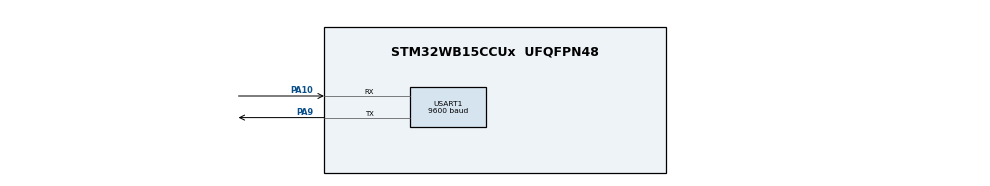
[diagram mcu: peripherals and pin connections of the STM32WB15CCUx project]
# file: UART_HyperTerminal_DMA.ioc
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Dma.Request0=USART1_RX
Dma.Request1=USART1_TX
Dma.USART1_RX.0.Direction=DMA_PERIPH_TO_MEMORY
Dma.USART1_RX.0.EventEnable=DISABLE
Dma.USART1_RX.0.Instance=DMA1_Channel2
Dma.USART1_RX.0.MemDataAlignment=DMA_MDATAALIGN_BYTE
Dma.USART1_RX.0.MemInc=DMA_MINC_ENABLE
Dma.USART1_RX.0.Mode=DMA_NORMAL
Dma.USART1_RX.0.PeriphDataAlignment=DMA_PDATAALIGN_BYTE
Dma.USART1_RX.0.PeriphInc=DMA_PINC_DISABLE
Dma.USART1_RX.0.Polarity=HAL_DMAMUX_REQ_GEN_RISING
Dma.USART1_RX.0.Priority=DMA_PRIORITY_HIGH
Dma.USART1_RX.0.RequestNumber=1
Dma.USART1_RX.0.SignalID=NONE
Dma.USART1_RX.0.SyncEnable=DISABLE
Dma.USART1_RX.0.SyncPolarity=HAL_DMAMUX_SYNC_NO_EVENT
Dma.USART1_RX.0.SyncRequestNumber=1
Dma.USART1_RX.0.SyncSignalID=NONE
Dma.USART1_TX.1.Direction=DMA_MEMORY_TO_PERIPH
Dma.USART1_TX.1.EventEnable=DISABLE
Dma.USART1_TX.1.Instance=DMA1_Channel1
Dma.USART1_TX.1.MemDataAlignment=DMA_MDATAALIGN_BYTE
Dma.USART1_TX.1.MemInc=DMA_MINC_ENABLE
Dma.USART1_TX.1.Mode=DMA_NORMAL
Dma.USART1_TX.1.PeriphDataAlignment=DMA_PDATAALIGN_BYTE
Dma.USART1_TX.1.PeriphInc=DMA_PINC_DISABLE
Dma.USART1_TX.1.Polarity=HAL_DMAMUX_REQ_GEN_RISING
Dma.USART1_TX.1.Priority=DMA_PRIORITY_LOW
Dma.USART1_TX.1.RequestNumber=1
Dma.USART1_TX.1.SignalID=NONE
Dma.USART1_TX.1.SyncEnable=DISABLE
Dma.USART1_TX.1.SyncPolarity=HAL_DMAMUX_SYNC_NO_EVENT
Dma.USART1_TX.1.SyncRequestNumber=1
Dma.USART1_TX.1.SyncSignalID=NONE
Mcu.Family=STM32WB
Mcu.Name=STM32WB15CCUx
Mcu.Package=UFQFPN48
NVIC.DMA1_Channel1_IRQn=true\:0\:0\:false\:false\:true\:true\:true
NVIC.DMA1_Channel2_IRQn=true\:0\:0\:false\:false\:true\:true\:true
NVIC.PriorityGroup=NVIC_PRIORITYGROUP_4
NVIC.USART1_IRQn=true\:0\:0\:false\:false\:true\:true\:true
PA10.GPIO_PuPd=GPIO_PULLUP
PA10.Mode=Asynchronous
PA10.Signal=USART1_RX
PA9.GPIO_PuPd=GPIO_PULLUP
PA9.Mode=Asynchronous
PA9.Signal=USART1_TX
ProjectManager.HeapSize=0x200
ProjectManager.StackSize=0x400
ProjectManager.TargetToolchain=EWARM V8
RCC.AHB2CLKDivider=RCC_SYSCLK_DIV2
RCC.AHBFreq_Value=64000000
RCC.APB1Freq_Value=64000000
RCC.APB1TimFreq_Value=64000000
RCC.APB2Freq_Value=64000000
RCC.APB2TimFreq_Value=64000000
RCC.APB3Freq_Value=16000000
RCC.CortexFreq_Value=64000000
RCC.HCLKFreq_Value=64000000
RCC.HSE_VALUE=8000000
RCC.HSI_VALUE=16000000
RCC.LSE_VALUE=32768
RCC.PLLN=32
RCC.SYSCLKFreq_VALUE=64000000
RCC.SYSCLKSource=RCC_SYSCLKSOURCE_PLLCLK
RCC.VCOOutputFreq_Value=128000000
USART1.AutoBaudRateEnableParam=UART_ADVFEATURE_AUTOBAUDRATE_DISABLE
USART1.BaudRate=9600
USART1.DMADisableonRxErrorParam=ADVFEATURE_DMA_ENABLEONRXERROR
USART1.DataInvertParam=ADVFEATURE_DATAINV_DISABLE
USART1.MSBFirstParam=ADVFEATURE_MSBFIRST_DISABLE
USART1.Mode=MODE_TX_RX
USART1.OneBitSampling=UART_ONE_BIT_SAMPLE_DISABLE
USART1.OverSampling=UART_OVERSAMPLING_16
USART1.OverrunDisableParam=ADVFEATURE_OVERRUN_ENABLE
USART1.Parity=PARITY_ODD
USART1.RxPinLevelInvertParam=ADVFEATURE_RXINV_DISABLE
USART1.StopBits=STOPBITS_1
USART1.SwapParam=ADVFEATURE_SWAP_DISABLE
USART1.TxPinLevelInvertParam=ADVFEATURE_TXINV_DISABLE
USART1.VirtualMode-Asynchronous=VM_ASYNC
USART1.WordLength=WORDLENGTH_8B
board=custom

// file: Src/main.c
/* USER CODE BEGIN Header */
/**
  ******************************************************************************
  * @file    UART/UART_HyperTerminal_DMA/Src/main.c
  * @author  MCD Application Team
  * @brief   This sample code shows how to use UART HAL API to transmit
  *          and receive a data buffer with a communication process based on
  *          DMA transfer.
  *          The communication is done with the Hyperterminal PC application.
  ******************************************************************************
  * @attention
  *
  * <h2><center>&copy; Copyright (c) 2019 STMicroelectronics.
  * All rights reserved.</center></h2>
  *
  * This software component is licensed by ST under BSD 3-Clause license,
  * the "License"; You may not use this file except in compliance with the
  * License. You may obtain a copy of the License at:
  *                        opensource.org/licenses/BSD-3-Clause
  *
  ******************************************************************************
  */
/* USER CODE END Header */
#include "main.h"

UART_HandleTypeDef huart1;
DMA_HandleTypeDef hdma_usart1_rx;
DMA_HandleTypeDef hdma_usart1_tx;

/* USER CODE BEGIN PV */
/* Buffer used for transmission */
uint8_t aTxStartMessage[] = "\n\r ****UART-Hyperterminal communication based on DMA****\n\r Enter 10 characters using keyboard :\n\r";
uint8_t aTxEndMessage[] = "\n\r Example Finished\n\r";

/* Buffer used for reception */
uint8_t aRxBuffer[RXBUFFERSIZE];
/* USER CODE END PV */

void SystemClock_Config(void);
static void MX_GPIO_Init(void);
static void MX_DMA_Init(void);
static void MX_USART1_UART_Init(void);

int main(void)
{
  /* USER CODE BEGIN 1 */

  /* STM32WBxx HAL library initialization:
       - Configure the Flash prefetch
       - Systick timer is configured by default as source of time base, but user
         can eventually implement his proper time base source (a general purpose
         timer for example or other time source), keeping in mind that Time base
         duration should be kept 1ms since PPP_TIMEOUT_VALUEs are defined and
         handled in milliseconds basis.
       - Set NVIC Group Priority to 4
       - Low Level Initialization
     */
  /* USER CODE END 1 */

  /* MCU Configuration--------------------------------------------------------*/

  /* Reset of all peripherals, Initializes the Flash interface and the Systick. */
  HAL_Init();

  /* Configure the system clock */
  SystemClock_Config();

  /* USER CODE BEGIN SysInit */
  /* Configure LED2 and LED3 */
  BSP_LED_Init(LED2);
  BSP_LED_Init(LED3);
  /* USER CODE END SysInit */

  /* Initialize all configured peripherals */
  MX_GPIO_Init();
  MX_DMA_Init();
  MX_USART1_UART_Init();
  /* USER CODE BEGIN 2 */

  /*##-1- Start the transmission process #####################################*/
  /* User start transmission data through "TxBuffer" buffer */
  if(HAL_UART_Transmit_DMA(&huart1, (uint8_t*)aTxStartMessage, TXSTARTMESSAGESIZE)!= HAL_OK)
  {
    /* Transfer error in transmission process */
    Error_Handler();
  }

  /*##-2- Put UART peripheral in reception process ###########################*/
  /* Any data received will be stored in "aRxBuffer" buffer : the number max of
     data received is 10 */
  if (HAL_UART_Receive_DMA(&huart1, (uint8_t *)aRxBuffer, RXBUFFERSIZE) != HAL_OK)
  {
    /* Transfer error in reception process */
    Error_Handler();
  }

  /*##-3- Wait for the end of the transfer ###################################*/
  /*  Before starting a new communication transfer, you need to check the current
      state of the peripheral; if it's busy you need to wait for the end of current
      transfer before starting a new one.
      For simplicity reasons, this example is just waiting till the end of the
      transfer, but application may perform other tasks while transfer operation
      is ongoing. */
  while (HAL_UART_GetState(&huart1) != HAL_UART_STATE_READY)
  {
  }

  /*##-4- Send the received Buffer ###########################################*/
  if (HAL_UART_Transmit_DMA(&huart1, (uint8_t *)aRxBuffer, RXBUFFERSIZE) != HAL_OK)
  {
    /* Transfer error in transmission process */
    Error_Handler();
  }

  /*##-5- Wait for the end of the transfer ###################################*/
  /*  Before starting a new communication transfer, you need to check the current
      state of the peripheral; if it's busy you need to wait for the end of current
      transfer before starting a new one.
      For simplicity reasons, this example is just waiting till the end of the
      transfer, but application may perform other tasks while transfer operation
      is ongoing. */
  while (HAL_UART_GetState(&huart1) != HAL_UART_STATE_READY)
  {
  }

  /*##-6- Send the End Message ###############################################*/
  if(HAL_UART_Transmit_DMA(&huart1, (uint8_t*)aTxEndMessage, TXENDMESSAGESIZE)!= HAL_OK)
  {
    /* Transfer error in transmission process */
    Error_Handler();
  }

  /*##-7- Wait for the end of the transfer ###################################*/
  while (HAL_UART_GetState(&huart1) != HAL_UART_STATE_READY)
  {
  }

  /* Turn on LED2 if test passes then enter infinite loop */
  BSP_LED_On(LED2);
  /* USER CODE END 2 */

  /* Infinite loop */
  while (1)
  {

  }
}

void SystemClock_Config(void)
{
  RCC_OscInitTypeDef RCC_OscInitStruct = {0};
  RCC_ClkInitTypeDef RCC_ClkInitStruct = {0};
  RCC_PeriphCLKInitTypeDef PeriphClkInitStruct = {0};

  /** Initializes the RCC Oscillators according to the specified parameters
  * in the RCC_OscInitTypeDef structure.
  */
  RCC_OscInitStruct.OscillatorType = RCC_OSCILLATORTYPE_HSI|RCC_OSCILLATORTYPE_MSI;
  RCC_OscInitStruct.HSIState = RCC_HSI_ON;
  RCC_OscInitStruct.MSIState = RCC_MSI_ON;
  RCC_OscInitStruct.HSICalibrationValue = RCC_HSICALIBRATION_DEFAULT;
  RCC_OscInitStruct.MSICalibrationValue = RCC_MSICALIBRATION_DEFAULT;
  RCC_OscInitStruct.MSIClockRange = RCC_MSIRANGE_6;
  RCC_OscInitStruct.PLL.PLLState = RCC_PLL_ON;
  RCC_OscInitStruct.PLL.PLLSource = RCC_PLLSOURCE_MSI;
  RCC_OscInitStruct.PLL.PLLM = RCC_PLLM_DIV1;
  RCC_OscInitStruct.PLL.PLLN = 32;
  RCC_OscInitStruct.PLL.PLLP = RCC_PLLP_DIV2;
  RCC_OscInitStruct.PLL.PLLR = RCC_PLLR_DIV2;
  RCC_OscInitStruct.PLL.PLLQ = RCC_PLLQ_DIV2;
  if (HAL_RCC_OscConfig(&RCC_OscInitStruct) != HAL_OK)
  {
    Error_Handler();
  }
  /** Configure the SYSCLKSource, HCLK, PCLK1 and PCLK2 clocks dividers
  */
  RCC_ClkInitStruct.ClockType = RCC_CLOCKTYPE_HCLK4|RCC_CLOCKTYPE_HCLK2
                              |RCC_CLOCKTYPE_HCLK|RCC_CLOCKTYPE_SYSCLK
                              |RCC_CLOCKTYPE_PCLK1|RCC_CLOCKTYPE_PCLK2;
  RCC_ClkInitStruct.SYSCLKSource = RCC_SYSCLKSOURCE_PLLCLK;
  RCC_ClkInitStruct.AHBCLKDivider = RCC_SYSCLK_DIV1;
  RCC_ClkInitStruct.APB1CLKDivider = RCC_HCLK_DIV1;
  RCC_ClkInitStruct.APB2CLKDivider = RCC_HCLK_DIV1;
  RCC_ClkInitStruct.AHBCLK2Divider = RCC_SYSCLK_DIV2;
  RCC_ClkInitStruct.AHBCLK4Divider = RCC_SYSCLK_DIV1;

  if (HAL_RCC_ClockConfig(&RCC_ClkInitStruct, FLASH_LATENCY_3) != HAL_OK)
  {
    Error_Handler();
  }
  /** Initializes the peripherals clocks
  */
  PeriphClkInitStruct.PeriphClockSelection = RCC_PERIPHCLK_SMPS|RCC_PERIPHCLK_USART1;
  PeriphClkInitStruct.Usart1ClockSelection = RCC_USART1CLKSOURCE_PCLK2;
  PeriphClkInitStruct.SmpsClockSelection = RCC_SMPSCLKSOURCE_HSI;
  PeriphClkInitStruct.SmpsDivSelection = RCC_SMPSCLKDIV_RANGE1;
  if (HAL_RCCEx_PeriphCLKConfig(&PeriphClkInitStruct) != HAL_OK)
  {
    Error_Handler();
  }
}

static void MX_USART1_UART_Init(void)
{

  huart1.Instance = USART1;
  huart1.Init.BaudRate = 9600;
  huart1.Init.WordLength = UART_WORDLENGTH_8B;
  huart1.Init.StopBits = UART_STOPBITS_1;
  huart1.Init.Parity = UART_PARITY_ODD;
  huart1.Init.Mode = UART_MODE_TX_RX;
  huart1.Init.HwFlowCtl = UART_HWCONTROL_NONE;
  huart1.Init.OverSampling = UART_OVERSAMPLING_16;
  huart1.Init.OneBitSampling = UART_ONE_BIT_SAMPLE_DISABLE;
  huart1.Init.ClockPrescaler = UART_PRESCALER_DIV1;
  huart1.AdvancedInit.AdvFeatureInit = UART_ADVFEATURE_NO_INIT;
  if (HAL_UART_Init(&huart1) != HAL_OK)
  {
    Error_Handler();
  }
  if (HAL_UARTEx_SetTxFifoThreshold(&huart1, UART_TXFIFO_THRESHOLD_1_8) != HAL_OK)
  {
    Error_Handler();
  }
  if (HAL_UARTEx_SetRxFifoThreshold(&huart1, UART_RXFIFO_THRESHOLD_1_8) != HAL_OK)
  {
    Error_Handler();
  }
  if (HAL_UARTEx_DisableFifoMode(&huart1) != HAL_OK)
  {
    Error_Handler();
  }

}

static void MX_DMA_Init(void)
{

  /* DMA controller clock enable */
  __HAL_RCC_DMAMUX1_CLK_ENABLE();
  __HAL_RCC_DMA1_CLK_ENABLE();

  /* DMA interrupt init */
  /* DMA1_Channel1_IRQn interrupt configuration */
  HAL_NVIC_SetPriority(DMA1_Channel1_IRQn, 0, 0);
  HAL_NVIC_EnableIRQ(DMA1_Channel1_IRQn);
  /* DMA1_Channel2_IRQn interrupt configuration */
  HAL_NVIC_SetPriority(DMA1_Channel2_IRQn, 0, 0);
  HAL_NVIC_EnableIRQ(DMA1_Channel2_IRQn);

}

static void MX_GPIO_Init(void)
{

  /* GPIO Ports Clock Enable */
  __HAL_RCC_GPIOA_CLK_ENABLE();

}

/* USER CODE BEGIN 4 */

/**
  * @brief  Tx Transfer completed callback
  * @param  huart: UART handle.
  * @note   This example shows a simple way to report end of DMA Tx transfer, and
  *         you can add your own implementation.
  * @retval None
  */
void HAL_UART_TxCpltCallback(UART_HandleTypeDef *huart)
{
}

/**
  * @brief  Rx Transfer completed callback
  * @param  huart: UART handle
  * @note   This example shows a simple way to report end of DMA Rx transfer, and
  *         you can add your own implementation.
  * @retval None
  */
void HAL_UART_RxCpltCallback(UART_HandleTypeDef *huart)
{
}

/**
  * @brief  UART error callbacks
  * @param  huart: UART handle
  * @note   This example shows a simple way to report transfer error, and you can
  *         add your own implementation.
  * @retval None
  */
void HAL_UART_ErrorCallback(UART_HandleTypeDef *huart)
{
  /* Turn LED3 on: Transfer error in reception/transmission process */
  BSP_LED_On(LED3);
}

/* USER CODE END 4 */

void Error_Handler(void)
{
  /* USER CODE BEGIN Error_Handler_Debug */
  /* User can add his own implementation to report the HAL error return state */
  /* Turn LED3 on */
  BSP_LED_On(LED3);
  while(1);
  /* USER CODE END Error_Handler_Debug */
}

/************************ (C) COPYRIGHT STMicroelectronics *****END OF FILE****/
